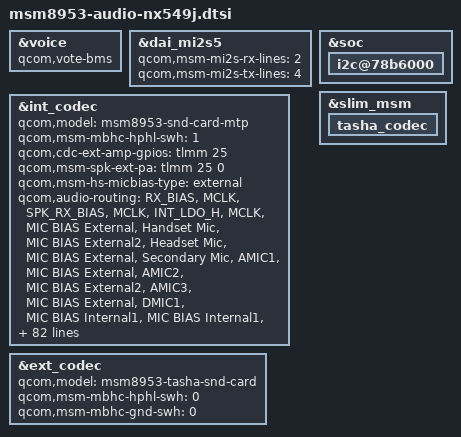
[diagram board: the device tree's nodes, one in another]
/*
 * Nubia NX549J audio overlay.
 *
 * Stock 3.18 NX549J disables the generic WSA/max989-style speaker path and
 * uses the internal PM8953 codec plus external amp GPIO wiring.
 */

&voice {
	qcom,vote-bms;
};

&dai_mi2s5 {
	qcom,msm-mi2s-rx-lines = <2>;
	qcom,msm-mi2s-tx-lines = <4>;
};

&int_codec {
	qcom,model = "msm8953-snd-card-mtp";
	qcom,msm-mbhc-hphl-swh = <1>;
	qcom,cdc-ext-amp-gpios = <&tlmm 25 0>;
	qcom,msm-spk-ext-pa = <&tlmm 25 0>;
	qcom,msm-hs-micbias-type = "external";

	/delete-property/ qcom,cdc-us-euro-gpios;
	/delete-property/ asoc-wsa-codec-names;
	/delete-property/ asoc-wsa-codec-prefixes;
	/delete-property/ msm-vdd-wsa-switch-supply;
	/delete-property/ qcom,msm-vdd-wsa-switch-voltage;
	/delete-property/ qcom,msm-vdd-wsa-switch-current;

	qcom,audio-routing =
		"RX_BIAS", "MCLK",
		"SPK_RX_BIAS", "MCLK",
		"INT_LDO_H", "MCLK",
		"MIC BIAS External", "Handset Mic",
		"MIC BIAS External2", "Headset Mic",
		"MIC BIAS External", "Secondary Mic",
		"AMIC1", "MIC BIAS External",
		"AMIC2", "MIC BIAS External2",
		"AMIC3", "MIC BIAS External",
		"DMIC1", "MIC BIAS Internal1",
		"MIC BIAS Internal1", "Digital Mic1",
		"DMIC2", "MIC BIAS Internal1",
		"MIC BIAS Internal1", "Digital Mic2",
		"DMIC3", "MIC BIAS External",
		"WSA_SPK OUT", "VDD_WSA_SWITCH",
		"SpkrMono WSA_IN", "WSA_SPK OUT";

	qcom,msm-gpios =
		"pri_i2s",
		"us_eu_gpio",
		"dmic_gpio",
		"comp_gpio";

	qcom,pinctrl-names =
		"all_off",
		"pri_i2s_act",
		"us_eu_gpio_act",
		"pri_i2s_us_eu_gpio_act",
		"dmic_act",
		"dmic_pri_i2s_act",
		"dmic_us_eu_gpio_act",
		"dmic_us_eu_gpio_pri_i2s_act",
		"comp_gpio_act",
		"comp_gpio_pri_i2s_act",
		"comp_gpio_us_eu_gpio_act",
		"comp_gpio_pri_i2s_us_eu_gpio_act",
		"comp_gpio_dmic_act",
		"comp_gpio_dmic_pri_i2s_act",
		"comp_gpio_dmic_us_eu_gpio_act",
		"comp_gpio_dmic_us_eu_gpio_pri_i2s_act";

	pinctrl-names =
		"all_off",
		"pri_i2s_act",
		"us_eu_gpio_act",
		"pri_i2s_us_eu_gpio_act",
		"dmic_act",
		"dmic_pri_i2s_act",
		"dmic_us_eu_gpio_act",
		"dmic_us_eu_gpio_pri_i2s_act",
		"comp_gpio_act",
		"comp_gpio_pri_i2s_act",
		"comp_gpio_us_eu_gpio_act",
		"comp_gpio_pri_i2s_us_eu_gpio_act",
		"comp_gpio_dmic_act",
		"comp_gpio_dmic_pri_i2s_act",
		"comp_gpio_dmic_us_eu_gpio_act",
		"comp_gpio_dmic_us_eu_gpio_pri_i2s_act";

	pinctrl-0 = <&cdc_pdm_lines_sus &cdc_pdm_comp_lines_sus
		&cdc_pdm_lines_2_sus &cross_conn_det_sus
		&cdc_dmic0_clk_sus &cdc_dmic0_data_sus &pri_tlmm_ws_sus>;
	pinctrl-1 = <&cdc_pdm_lines_act &cdc_pdm_comp_lines_sus
		&cdc_pdm_lines_2_act &cross_conn_det_sus
		&cdc_dmic0_clk_sus &cdc_dmic0_data_sus &pri_tlmm_ws_sus>;
	pinctrl-2 = <&cdc_pdm_lines_sus &cdc_pdm_comp_lines_sus
		&cdc_pdm_lines_2_sus &cross_conn_det_act
		&cdc_dmic0_clk_sus &cdc_dmic0_data_sus &pri_tlmm_ws_sus>;
	pinctrl-3 = <&cdc_pdm_lines_act &cdc_pdm_comp_lines_sus
		&cdc_pdm_lines_2_act &cross_conn_det_act
		&cdc_dmic0_clk_sus &cdc_dmic0_data_sus &pri_tlmm_ws_sus>;
	pinctrl-4 = <&cdc_pdm_lines_sus &cdc_pdm_comp_lines_sus
		&cdc_pdm_lines_2_sus &cross_conn_det_sus
		&cdc_dmic0_clk_act &cdc_dmic0_data_act &pri_tlmm_ws_act>;
	pinctrl-5 = <&cdc_pdm_lines_act &cdc_pdm_comp_lines_sus
		&cdc_pdm_lines_2_act &cross_conn_det_sus
		&cdc_dmic0_clk_act &cdc_dmic0_data_act &pri_tlmm_ws_act>;
	pinctrl-6 = <&cdc_pdm_lines_sus &cdc_pdm_comp_lines_sus
		&cdc_pdm_lines_2_sus &cross_conn_det_act
		&cdc_dmic0_clk_act &cdc_dmic0_data_act &pri_tlmm_ws_act>;
	pinctrl-7 = <&cdc_pdm_lines_act &cdc_pdm_comp_lines_sus
		&cdc_pdm_lines_2_act &cross_conn_det_act
		&cdc_dmic0_clk_act &cdc_dmic0_data_act &pri_tlmm_ws_act>;
	pinctrl-8 = <&cdc_pdm_lines_sus &cdc_pdm_comp_lines_act
		&cdc_pdm_lines_2_sus &cross_conn_det_sus
		&cdc_dmic0_clk_sus &cdc_dmic0_data_sus &pri_tlmm_ws_sus>;
	pinctrl-9 = <&cdc_pdm_lines_act &cdc_pdm_comp_lines_act
		&cdc_pdm_lines_2_act &cross_conn_det_sus
		&cdc_dmic0_clk_sus &cdc_dmic0_data_sus &pri_tlmm_ws_sus>;
	pinctrl-10 = <&cdc_pdm_lines_sus &cdc_pdm_comp_lines_act
		&cdc_pdm_lines_2_sus &cross_conn_det_act
		&cdc_dmic0_clk_sus &cdc_dmic0_data_sus &pri_tlmm_ws_sus>;
	pinctrl-11 = <&cdc_pdm_lines_act &cdc_pdm_comp_lines_act
		&cdc_pdm_lines_2_act &cross_conn_det_act
		&cdc_dmic0_clk_sus &cdc_dmic0_data_sus &pri_tlmm_ws_sus>;
	pinctrl-12 = <&cdc_pdm_lines_sus &cdc_pdm_comp_lines_act
		&cdc_pdm_lines_2_sus &cross_conn_det_sus
		&cdc_dmic0_clk_act &cdc_dmic0_data_act &pri_tlmm_ws_act>;
	pinctrl-13 = <&cdc_pdm_lines_act &cdc_pdm_comp_lines_act
		&cdc_pdm_lines_2_act &cross_conn_det_sus
		&cdc_dmic0_clk_act &cdc_dmic0_data_act &pri_tlmm_ws_act>;
	pinctrl-14 = <&cdc_pdm_lines_sus &cdc_pdm_comp_lines_act
		&cdc_pdm_lines_2_sus &cross_conn_det_act
		&cdc_dmic0_clk_act &cdc_dmic0_data_act &pri_tlmm_ws_act>;
	pinctrl-15 = <&cdc_pdm_lines_act &cdc_pdm_comp_lines_act
		&cdc_pdm_lines_2_act &cross_conn_det_act
		&cdc_dmic0_clk_act &cdc_dmic0_data_act &pri_tlmm_ws_act>;
};

&ext_codec {
	qcom,model = "msm8953-tasha-snd-card";
	qcom,msm-mbhc-hphl-swh = <0>;
	qcom,msm-mbhc-gnd-swh = <0>;

	/delete-property/ qcom,wsa-max-devs;
	/delete-property/ qcom,wsa-devs;
	/delete-property/ qcom,wsa-aux-dev-prefix;
	/delete-property/ qcom,cdc-us-euro-gpios;
};

&soc {
	i2c@78b6000 {
		/delete-node/ wsa881x-i2c-codec@f;
		/delete-node/ wsa881x-i2c-codec@45;
	};
};

&slim_msm {
	tasha_codec {
		/delete-node/ swr_master;
	};
};
